# STM32H747ZIY6@M4 register map
File version: 1.0
Registers are 32-bit, access not given, reset 0x0 unless marked. A register's access mark holds for its fields unless they carry their own. Offsets are from the block's base; [hi:lo] are bit positions.

## DMA2D
Base 0x52001000
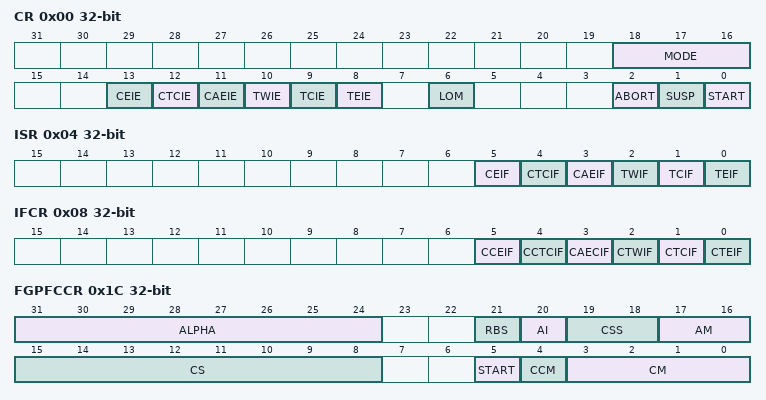
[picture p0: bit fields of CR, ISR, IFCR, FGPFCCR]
0x00 CR
  [18:16] MODE, [13] CEIE, [12] CTCIE, [11] CAEIE, [10] TWIE, [9] TCIE, [8] TEIE, [6] LOM, [2] ABORT, [1] SUSP, [0] START
0x04 ISR
  [5] CEIF, [4] CTCIF, [3] CAEIF, [2] TWIF, [1] TCIF, [0] TEIF
0x08 IFCR
  [5] CCEIF, [4] CCTCIF, [3] CAECIF, [2] CTWIF, [1] CTCIF, [0] CTEIF
0x0C FGMAR
  [31:0] MA
0x10 FGOR
  [15:0] LO
0x14 BGMAR
  [31:0] MA
0x18 BGOR
  [15:0] LO
0x1C FGPFCCR
  [31:24] ALPHA, [21] RBS, [20] AI, [19:18] CSS, [17:16] AM, [15:8] CS, [5] START, [4] CCM, [3:0] CM
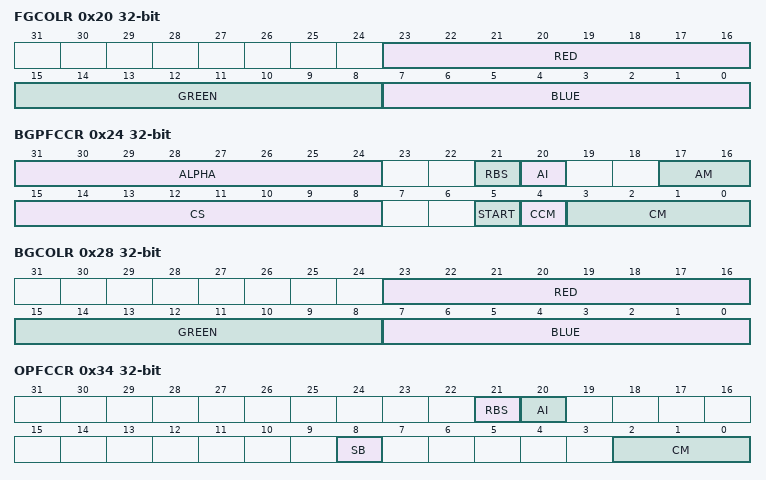
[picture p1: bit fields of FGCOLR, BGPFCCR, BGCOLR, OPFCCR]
0x20 FGCOLR
  [23:16] RED, [15:8] GREEN, [7:0] BLUE
0x24 BGPFCCR
  [31:24] ALPHA, [21] RBS, [20] AI, [17:16] AM, [15:8] CS, [5] START, [4] CCM, [3:0] CM
0x28 BGCOLR
  [23:16] RED, [15:8] GREEN, [7:0] BLUE
0x2C FGCMAR
  [31:0] MA
0x30 BGCMAR
  [31:0] MA
0x34 OPFCCR
  [21] RBS, [20] AI, [8] SB, [2:0] CM
0x38 OCOLR
  [31:24] ALPHA_1, [23:16] RED_1, [15] ALPHA_3, [15:12] ALPHA_4, [18:11] RED_2, [16:10] RED_3, [11:8] RED_4, [10:5] GREEN_3, [7:4] GREEN_4, [3:0] BLUE_4
0x3C OMAR
  [31:0] MA
0x40 OOR
  [15:0] LO
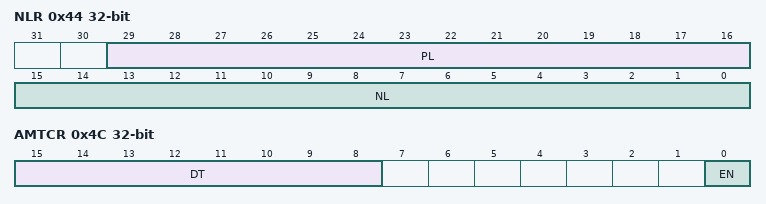
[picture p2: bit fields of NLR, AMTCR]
0x44 NLR
  [29:16] PL, [15:0] NL
0x48 LWR
  [15:0] LW
0x4C AMTCR
  [15:8] DT, [0] EN
0x400 FGCLUT.0
0x404 FGCLUT.1
0x408 FGCLUT.2
0x40C FGCLUT.3
0x410 FGCLUT.4
0x414 FGCLUT.5
0x418 FGCLUT.6
0x41C FGCLUT.7
0x420 FGCLUT.8
0x424 FGCLUT.9
0x428 FGCLUT.10
0x42C FGCLUT.11
0x430 FGCLUT.12
0x434 FGCLUT.13
0x438 FGCLUT.14
0x43C FGCLUT.15
0x440 FGCLUT.16
0x444 FGCLUT.17
0x448 FGCLUT.18
0x44C FGCLUT.19
0x450 FGCLUT.20
0x454 FGCLUT.21
0x458 FGCLUT.22
0x45C FGCLUT.23
0x460 FGCLUT.24
0x464 FGCLUT.25
0x468 FGCLUT.26
0x46C FGCLUT.27
0x470 FGCLUT.28
0x474 FGCLUT.29
0x478 FGCLUT.30
0x47C FGCLUT.31
0x480 FGCLUT.32
0x484 FGCLUT.33
0x488 FGCLUT.34
0x48C FGCLUT.35
0x490 FGCLUT.36
0x494 FGCLUT.37
0x498 FGCLUT.38
0x49C FGCLUT.39
0x4A0 FGCLUT.40
0x4A4 FGCLUT.41
0x4A8 FGCLUT.42
0x4AC FGCLUT.43
0x4B0 FGCLUT.44
0x4B4 FGCLUT.45
0x4B8 FGCLUT.46
0x4BC FGCLUT.47
0x4C0 FGCLUT.48
0x4C4 FGCLUT.49
0x4C8 FGCLUT.50
0x4CC FGCLUT.51
0x4D0 FGCLUT.52
0x4D4 FGCLUT.53
0x4D8 FGCLUT.54
0x4DC FGCLUT.55
0x4E0 FGCLUT.56
0x4E4 FGCLUT.57
0x4E8 FGCLUT.58
0x4EC FGCLUT.59
0x4F0 FGCLUT.60
0x4F4 FGCLUT.61
0x4F8 FGCLUT.62
0x4FC FGCLUT.63
0x500 FGCLUT.64
0x504 FGCLUT.65
0x508 FGCLUT.66
0x50C FGCLUT.67
0x510 FGCLUT.68
0x514 FGCLUT.69
0x518 FGCLUT.70
0x51C FGCLUT.71
0x520 FGCLUT.72
0x524 FGCLUT.73
0x528 FGCLUT.74
0x52C FGCLUT.75
0x530 FGCLUT.76
0x534 FGCLUT.77
0x538 FGCLUT.78
0x53C FGCLUT.79
0x540 FGCLUT.80
0x544 FGCLUT.81
0x548 FGCLUT.82
0x54C FGCLUT.83
0x550 FGCLUT.84
0x554 FGCLUT.85
0x558 FGCLUT.86
0x55C FGCLUT.87
0x560 FGCLUT.88
0x564 FGCLUT.89
0x568 FGCLUT.90
0x56C FGCLUT.91
0x570 FGCLUT.92
0x574 FGCLUT.93
0x578 FGCLUT.94
0x57C FGCLUT.95
0x580 FGCLUT.96
0x584 FGCLUT.97
0x588 FGCLUT.98
0x58C FGCLUT.99
0x590 FGCLUT.100
0x594 FGCLUT.101
0x598 FGCLUT.102
0x59C FGCLUT.103
0x5A0 FGCLUT.104
0x5A4 FGCLUT.105
0x5A8 FGCLUT.106
0x5AC FGCLUT.107
0x5B0 FGCLUT.108
0x5B4 FGCLUT.109
0x5B8 FGCLUT.110
0x5BC FGCLUT.111
0x5C0 FGCLUT.112
0x5C4 FGCLUT.113
0x5C8 FGCLUT.114
0x5CC FGCLUT.115
0x5D0 FGCLUT.116
0x5D4 FGCLUT.117
0x5D8 FGCLUT.118
0x5DC FGCLUT.119
0x5E0 FGCLUT.120
0x5E4 FGCLUT.121
0x5E8 FGCLUT.122
0x5EC FGCLUT.123
0x5F0 FGCLUT.124
0x5F4 FGCLUT.125
0x5F8 FGCLUT.126
0x5FC FGCLUT.127
0x600 FGCLUT.128
0x604 FGCLUT.129
0x608 FGCLUT.130
0x60C FGCLUT.131
0x610 FGCLUT.132
0x614 FGCLUT.133
0x618 FGCLUT.134
0x61C FGCLUT.135
0x620 FGCLUT.136
0x624 FGCLUT.137
0x628 FGCLUT.138
0x62C FGCLUT.139
0x630 FGCLUT.140
0x634 FGCLUT.141
0x638 FGCLUT.142
0x63C FGCLUT.143
0x640 FGCLUT.144
0x644 FGCLUT.145
0x648 FGCLUT.146
0x64C FGCLUT.147
0x650 FGCLUT.148
0x654 FGCLUT.149
0x658 FGCLUT.150
0x65C FGCLUT.151
0x660 FGCLUT.152
0x664 FGCLUT.153
0x668 FGCLUT.154
0x66C FGCLUT.155
0x670 FGCLUT.156
0x674 FGCLUT.157
0x678 FGCLUT.158
0x67C FGCLUT.159
0x680 FGCLUT.160
0x684 FGCLUT.161
0x688 FGCLUT.162
0x68C FGCLUT.163
0x690 FGCLUT.164
0x694 FGCLUT.165
0x698 FGCLUT.166
0x69C FGCLUT.167
0x6A0 FGCLUT.168
0x6A4 FGCLUT.169
0x6A8 FGCLUT.170
0x6AC FGCLUT.171
0x6B0 FGCLUT.172
0x6B4 FGCLUT.173
0x6B8 FGCLUT.174
0x6BC FGCLUT.175
0x6C0 FGCLUT.176
0x6C4 FGCLUT.177
0x6C8 FGCLUT.178
0x6CC FGCLUT.179
0x6D0 FGCLUT.180
0x6D4 FGCLUT.181
0x6D8 FGCLUT.182
0x6DC FGCLUT.183
0x6E0 FGCLUT.184
0x6E4 FGCLUT.185
0x6E8 FGCLUT.186
0x6EC FGCLUT.187
0x6F0 FGCLUT.188
0x6F4 FGCLUT.189
0x6F8 FGCLUT.190
0x6FC FGCLUT.191
0x700 FGCLUT.192
0x704 FGCLUT.193
0x708 FGCLUT.194
0x70C FGCLUT.195
0x710 FGCLUT.196
0x714 FGCLUT.197
0x718 FGCLUT.198
0x71C FGCLUT.199
0x720 FGCLUT.200
0x724 FGCLUT.201
0x728 FGCLUT.202
0x72C FGCLUT.203
0x730 FGCLUT.204
0x734 FGCLUT.205
0x738 FGCLUT.206
0x73C FGCLUT.207
0x740 FGCLUT.208
0x744 FGCLUT.209
0x748 FGCLUT.210
0x74C FGCLUT.211
0x750 FGCLUT.212
0x754 FGCLUT.213
0x758 FGCLUT.214
0x75C FGCLUT.215
0x760 FGCLUT.216
0x764 FGCLUT.217
0x768 FGCLUT.218
0x76C FGCLUT.219
0x770 FGCLUT.220
0x774 FGCLUT.221
0x778 FGCLUT.222
0x77C FGCLUT.223
0x780 FGCLUT.224
0x784 FGCLUT.225
0x788 FGCLUT.226
0x78C FGCLUT.227
0x790 FGCLUT.228
0x794 FGCLUT.229
0x798 FGCLUT.230
0x79C FGCLUT.231
0x7A0 FGCLUT.232
0x7A4 FGCLUT.233
0x7A8 FGCLUT.234
0x7AC FGCLUT.235
0x7B0 FGCLUT.236
0x7B4 FGCLUT.237
0x7B8 FGCLUT.238
0x7BC FGCLUT.239
0x7C0 FGCLUT.240
0x7C4 FGCLUT.241
0x7C8 FGCLUT.242
0x7CC FGCLUT.243
0x7D0 FGCLUT.244
0x7D4 FGCLUT.245
0x7D8 FGCLUT.246
0x7DC FGCLUT.247
0x7E0 FGCLUT.248
0x7E4 FGCLUT.249
0x7E8 FGCLUT.250
0x7EC FGCLUT.251
0x7F0 FGCLUT.252
0x7F4 FGCLUT.253
0x7F8 FGCLUT.254
0x7FC FGCLUT.255
0x800 BGCLUT.0
0x804 BGCLUT.1
0x808 BGCLUT.2
0x80C BGCLUT.3
0x810 BGCLUT.4
0x814 BGCLUT.5
0x818 BGCLUT.6
0x81C BGCLUT.7
0x820 BGCLUT.8
0x824 BGCLUT.9
0x828 BGCLUT.10
0x82C BGCLUT.11
0x830 BGCLUT.12
0x834 BGCLUT.13
0x838 BGCLUT.14
0x83C BGCLUT.15
0x840 BGCLUT.16
0x844 BGCLUT.17
0x848 BGCLUT.18
0x84C BGCLUT.19
0x850 BGCLUT.20
0x854 BGCLUT.21
0x858 BGCLUT.22
0x85C BGCLUT.23
0x860 BGCLUT.24
0x864 BGCLUT.25
0x868 BGCLUT.26
0x86C BGCLUT.27
0x870 BGCLUT.28
0x874 BGCLUT.29
0x878 BGCLUT.30
0x87C BGCLUT.31
0x880 BGCLUT.32
0x884 BGCLUT.33
0x888 BGCLUT.34
0x88C BGCLUT.35
0x890 BGCLUT.36
0x894 BGCLUT.37
0x898 BGCLUT.38
0x89C BGCLUT.39
0x8A0 BGCLUT.40
0x8A4 BGCLUT.41
0x8A8 BGCLUT.42
0x8AC BGCLUT.43
0x8B0 BGCLUT.44
0x8B4 BGCLUT.45
0x8B8 BGCLUT.46
0x8BC BGCLUT.47
0x8C0 BGCLUT.48
0x8C4 BGCLUT.49
0x8C8 BGCLUT.50
0x8CC BGCLUT.51
0x8D0 BGCLUT.52
0x8D4 BGCLUT.53
0x8D8 BGCLUT.54
0x8DC BGCLUT.55
0x8E0 BGCLUT.56
0x8E4 BGCLUT.57
0x8E8 BGCLUT.58
0x8EC BGCLUT.59
0x8F0 BGCLUT.60
0x8F4 BGCLUT.61
0x8F8 BGCLUT.62
0x8FC BGCLUT.63
0x900 BGCLUT.64
0x904 BGCLUT.65
0x908 BGCLUT.66
0x90C BGCLUT.67
0x910 BGCLUT.68
0x914 BGCLUT.69
0x918 BGCLUT.70
0x91C BGCLUT.71
0x920 BGCLUT.72
0x924 BGCLUT.73
0x928 BGCLUT.74
0x92C BGCLUT.75
0x930 BGCLUT.76
0x934 BGCLUT.77
0x938 BGCLUT.78
0x93C BGCLUT.79
0x940 BGCLUT.80
0x944 BGCLUT.81
0x948 BGCLUT.82
0x94C BGCLUT.83
0x950 BGCLUT.84
0x954 BGCLUT.85
0x958 BGCLUT.86
0x95C BGCLUT.87
0x960 BGCLUT.88
0x964 BGCLUT.89
0x968 BGCLUT.90
0x96C BGCLUT.91
0x970 BGCLUT.92
0x974 BGCLUT.93
0x978 BGCLUT.94
0x97C BGCLUT.95
0x980 BGCLUT.96
0x984 BGCLUT.97
0x988 BGCLUT.98
0x98C BGCLUT.99
0x990 BGCLUT.100
0x994 BGCLUT.101
0x998 BGCLUT.102
0x99C BGCLUT.103
0x9A0 BGCLUT.104
0x9A4 BGCLUT.105
0x9A8 BGCLUT.106
0x9AC BGCLUT.107
0x9B0 BGCLUT.108
0x9B4 BGCLUT.109
0x9B8 BGCLUT.110
0x9BC BGCLUT.111
0x9C0 BGCLUT.112
0x9C4 BGCLUT.113
0x9C8 BGCLUT.114
0x9CC BGCLUT.115
0x9D0 BGCLUT.116
0x9D4 BGCLUT.117
0x9D8 BGCLUT.118
0x9DC BGCLUT.119
0x9E0 BGCLUT.120
0x9E4 BGCLUT.121
0x9E8 BGCLUT.122
0x9EC BGCLUT.123
0x9F0 BGCLUT.124
0x9F4 BGCLUT.125
0x9F8 BGCLUT.126
0x9FC BGCLUT.127
0xA00 BGCLUT.128
0xA04 BGCLUT.129
0xA08 BGCLUT.130
0xA0C BGCLUT.131
0xA10 BGCLUT.132
0xA14 BGCLUT.133
0xA18 BGCLUT.134
0xA1C BGCLUT.135
0xA20 BGCLUT.136
0xA24 BGCLUT.137
0xA28 BGCLUT.138
0xA2C BGCLUT.139
0xA30 BGCLUT.140
0xA34 BGCLUT.141
0xA38 BGCLUT.142
0xA3C BGCLUT.143
0xA40 BGCLUT.144
0xA44 BGCLUT.145
0xA48 BGCLUT.146
0xA4C BGCLUT.147
0xA50 BGCLUT.148
0xA54 BGCLUT.149
0xA58 BGCLUT.150
0xA5C BGCLUT.151
0xA60 BGCLUT.152
0xA64 BGCLUT.153
0xA68 BGCLUT.154
0xA6C BGCLUT.155
0xA70 BGCLUT.156
0xA74 BGCLUT.157
0xA78 BGCLUT.158
0xA7C BGCLUT.159
0xA80 BGCLUT.160
0xA84 BGCLUT.161
0xA88 BGCLUT.162
0xA8C BGCLUT.163
0xA90 BGCLUT.164
0xA94 BGCLUT.165
0xA98 BGCLUT.166
0xA9C BGCLUT.167
0xAA0 BGCLUT.168
0xAA4 BGCLUT.169
0xAA8 BGCLUT.170
0xAAC BGCLUT.171
0xAB0 BGCLUT.172
0xAB4 BGCLUT.173
0xAB8 BGCLUT.174
0xABC BGCLUT.175
0xAC0 BGCLUT.176
0xAC4 BGCLUT.177
0xAC8 BGCLUT.178
0xACC BGCLUT.179
0xAD0 BGCLUT.180
0xAD4 BGCLUT.181
0xAD8 BGCLUT.182
0xADC BGCLUT.183
0xAE0 BGCLUT.184
0xAE4 BGCLUT.185
0xAE8 BGCLUT.186
0xAEC BGCLUT.187
0xAF0 BGCLUT.188
0xAF4 BGCLUT.189
0xAF8 BGCLUT.190
0xAFC BGCLUT.191
0xB00 BGCLUT.192
0xB04 BGCLUT.193
0xB08 BGCLUT.194
0xB0C BGCLUT.195
0xB10 BGCLUT.196
0xB14 BGCLUT.197
0xB18 BGCLUT.198
0xB1C BGCLUT.199
0xB20 BGCLUT.200
0xB24 BGCLUT.201
0xB28 BGCLUT.202
0xB2C BGCLUT.203
0xB30 BGCLUT.204
0xB34 BGCLUT.205
0xB38 BGCLUT.206
0xB3C BGCLUT.207
0xB40 BGCLUT.208
0xB44 BGCLUT.209
0xB48 BGCLUT.210
0xB4C BGCLUT.211
0xB50 BGCLUT.212
0xB54 BGCLUT.213
0xB58 BGCLUT.214
0xB5C BGCLUT.215
0xB60 BGCLUT.216
0xB64 BGCLUT.217
0xB68 BGCLUT.218
0xB6C BGCLUT.219
0xB70 BGCLUT.220
0xB74 BGCLUT.221
0xB78 BGCLUT.222
0xB7C BGCLUT.223
0xB80 BGCLUT.224
0xB84 BGCLUT.225
0xB88 BGCLUT.226
0xB8C BGCLUT.227
0xB90 BGCLUT.228
0xB94 BGCLUT.229
0xB98 BGCLUT.230
0xB9C BGCLUT.231
0xBA0 BGCLUT.232
0xBA4 BGCLUT.233
0xBA8 BGCLUT.234
0xBAC BGCLUT.235
0xBB0 BGCLUT.236
0xBB4 BGCLUT.237
0xBB8 BGCLUT.238
0xBBC BGCLUT.239
0xBC0 BGCLUT.240
0xBC4 BGCLUT.241
0xBC8 BGCLUT.242
0xBCC BGCLUT.243
0xBD0 BGCLUT.244
0xBD4 BGCLUT.245
0xBD8 BGCLUT.246
0xBDC BGCLUT.247
0xBE0 BGCLUT.248
0xBE4 BGCLUT.249
0xBE8 BGCLUT.250
0xBEC BGCLUT.251
0xBF0 BGCLUT.252
0xBF4 BGCLUT.253
0xBF8 BGCLUT.254
0xBFC BGCLUT.255
